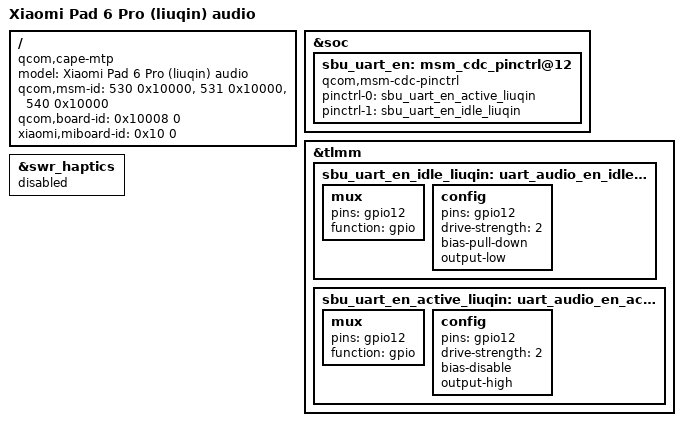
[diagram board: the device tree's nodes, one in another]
/dts-v1/;
/plugin/;

#include "xiaomi-sm8450-common.dtsi"

/ {
	model = "Xiaomi Pad 6 Pro (liuqin) audio";
	compatible = "qcom,cape-mtp", "qcom,cape", "qcom,mtp";
	qcom,msm-id = <530 0x10000>, <531 0x10000>, <540 0x10000>;
	qcom,board-id = <0x10008 0>;
	xiaomi,miboard-id = <0x10 0>;
};

&soc {
	sbu_uart_en: msm_cdc_pinctrl@12 {
		compatible = "qcom,msm-cdc-pinctrl";
		pinctrl-names = "aud_active", "aud_sleep";
		pinctrl-0 = <&sbu_uart_en_active_liuqin>;
		pinctrl-1 = <&sbu_uart_en_idle_liuqin>;
		#gpio-cells = <0>;
	};
};

&tlmm {
	sbu_uart_en_idle_liuqin: uart_audio_en_idle_liuqin {
		mux {
			pins = "gpio12";
			function = "gpio";
		};

		config {
			pins = "gpio12";
			drive-strength = <2>;
			bias-pull-down;
			output-low;
		};
	};

	sbu_uart_en_active_liuqin: uart_audio_en_active_liuqin {
		mux {
			pins = "gpio12";
			function = "gpio";
		};

		config {
			pins = "gpio12";
			drive-strength = <2>;
			bias-disable;
			output-high;
		};
	};
};

/* liuqin has no vibration motor; the PMIC SoundWire node is platform-only. */
&swr_haptics {
	status = "disabled";
};
